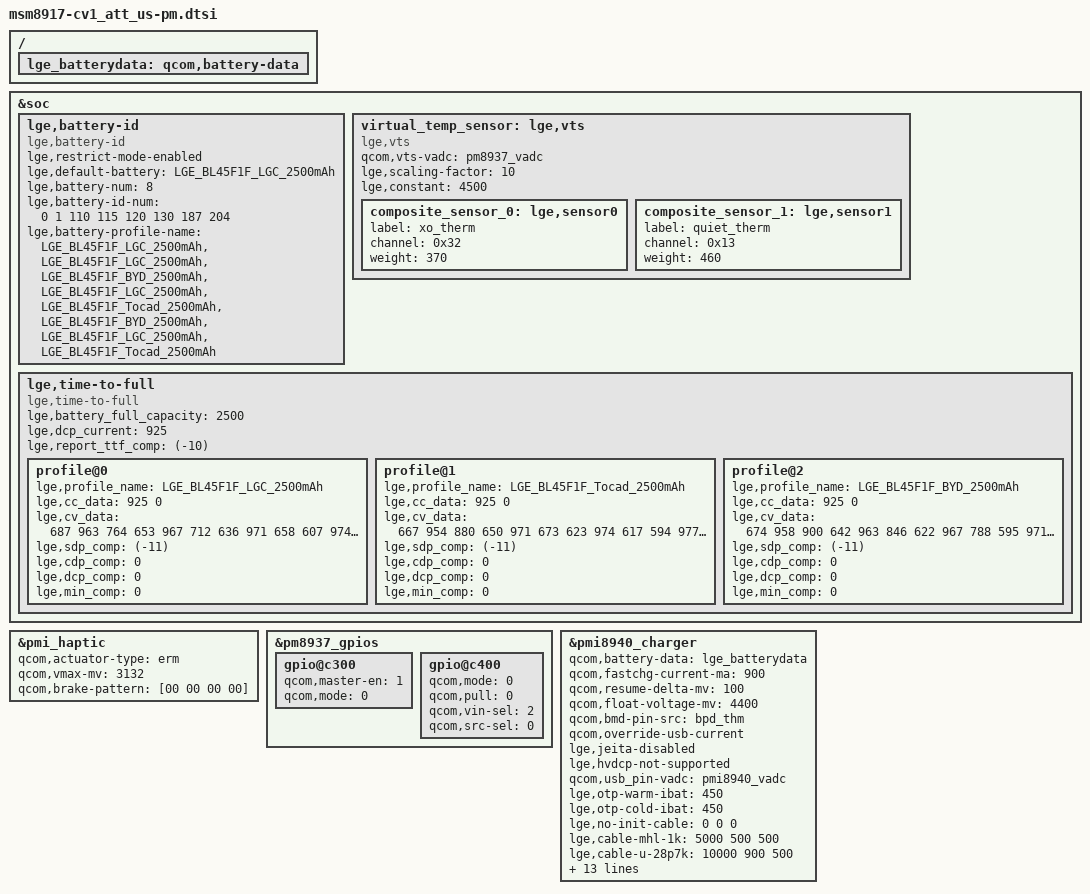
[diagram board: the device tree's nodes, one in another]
/*
 * Copyright (c) 2016, The Linux Foundation. All rights reserved.
 *
 * This program is free software; you can redistribute it and/or modify
 * it under the terms of the GNU General Public License version 2 and
 * only version 2 as published by the Free Software Foundation.
 *
 * This program is distributed in the hope that it will be useful,
 * but WITHOUT ANY WARRANTY; without even the implied warranty of
 * MERCHANTABILITY or FITNESS FOR A PARTICULAR PURPOSE.  See the
 * GNU General Public License for more details.
 */

/{
    lge_batterydata: qcom,battery-data {
         #include "../battery_profile/LGE_BL45F1F_LGC_2500mAh.dtsi"
         #include "../battery_profile/LGE_BL45F1F_Tocad_2500mAh.dtsi"
         #include "../battery_profile/LGE_BL45F1F_BYD_2500mAh.dtsi"
    };
};

&soc {
	lge,battery-id{
		compatible = "lge,battery-id";
		lge,restrict-mode-enabled;
		/*default battery profile*/
		lge,default-battery = "LGE_BL45F1F_LGC_2500mAh";
		/*Total number of combined of battery cell and battery id */
		lge,battery-num = <8>;
		/* battery id and battery profile match numbers */
		lge,battery-id-num = <0 1 110 115 120 130 187 204>;
		/* battery profile */
		lge,battery-profile-name = "LGE_BL45F1F_LGC_2500mAh",
						"LGE_BL45F1F_LGC_2500mAh",
						"LGE_BL45F1F_BYD_2500mAh",
						"LGE_BL45F1F_LGC_2500mAh",
						"LGE_BL45F1F_Tocad_2500mAh",
						"LGE_BL45F1F_BYD_2500mAh",
						"LGE_BL45F1F_LGC_2500mAh",
						"LGE_BL45F1F_Tocad_2500mAh";
	};

	/* vts = (0.37*xo_therm) + (0.46*quiet_therm) + 4.5 */
	virtual_temp_sensor: lge,vts {
		compatible = "lge,vts";
		qcom,vts-vadc = <&pm8937_vadc>;
		lge,scaling-factor= <10>;
		lge,constant = <4500>;
		composite_sensor_0: lge,sensor0 {
			label = "xo_therm";
			channel = <0x32>;
			weight = <370>;
		};
		composite_sensor_1: lge,sensor1 {
			label = "quiet_therm";
			channel = <0x13>;
			weight = <460>;
		};
	};

	/* time to full */
	lge,time-to-full {
		compatible = "lge,time-to-full";
		lge,battery_full_capacity = <2500>;
		lge,dcp_current = <925>;
		lge,report_ttf_comp = <(-10)>;
		profile@0 {
			lge,profile_name = "LGE_BL45F1F_LGC_2500mAh";
				    /* current  soc */
			lge,cc_data = < 925 0 >;
				    /* current  soc    time */
			lge,cv_data = < 687 963 764
							653 967 712
							636 971 658
							607 974 601
							587 977 542
							558 980 482
							540 983 420
							511 986 355
							490 989 289
							469 993 220
							452 996 150
							428 999 76
							411 1000 0 >;
			lge,sdp_comp = <(-11)>;
			lge,cdp_comp = <0>;
			lge,dcp_comp = <0>;
			lge,min_comp = <0>;
		};
		profile@1 {
			lge,profile_name = "LGE_BL45F1F_Tocad_2500mAh";
				    /* current  soc */
			lge,cc_data = < 925 0 >;
				    /* current  soc    time */
			lge,cv_data = < 667 954 880
							650 971 673
							623 974 617
							594 977 556
							568 980 495
							546 983 429
							520 986 363
							502 989 295
							472 993 225
							453 996 152
							425 999 77
							412 1000 0 >;
			lge,sdp_comp = <(-11)>;
			lge,cdp_comp = <0>;
			lge,dcp_comp = <0>;
			lge,min_comp = <0>;
		};
		profile@2 {
			lge,profile_name = "LGE_BL45F1F_BYD_2500mAh";
				    /* current  soc */
			lge,cc_data = < 925 0 >;
				    /* current  soc    time */
			lge,cv_data = < 674 958 900
							642 963 846
							622 967 788
							595 971 728
							574 974 667
							545 977 603
							531 980 537
							500 983 468
							482 986 398
							455 989 325
							438 993 247
							414 996 168
							399 999 86
							374 1000 0 >;
			lge,sdp_comp = <(-11)>;
			lge,cdp_comp = <0>;
			lge,dcp_comp = <0>;
			lge,min_comp = <0>;
		};
	};
};

&pmi_haptic{
	status = "okay";
	qcom,actuator-type = "erm";
	qcom,vmax-mv = <3132>;
	qcom,brake-pattern = [00 00 00 00];
};

&pm8937_gpios {
	gpio@c300 {
		qcom,master-en = <1>;
		qcom,mode = <0>;
		status = "okay";
	};

	gpio@c400 {
		qcom,mode = <0>;
		qcom,pull = <0>;
		qcom,vin-sel = <2>;
		qcom,src-sel = <0>;
		status = "okay";
	};
};

&pmi8940_charger {
	qcom,battery-data = <&lge_batterydata>;
	qcom,fastchg-current-ma = <900>;
	qcom,resume-delta-mv = <100>;
	qcom,float-voltage-mv = <4400>;
	qcom,bmd-pin-src = "bpd_thm";
	qcom,override-usb-current;
	lge,jeita-disabled;
	lge,hvdcp-not-supported;

	qcom,usb_pin-vadc = <&pmi8940_vadc>;

	lge,otp-warm-ibat = <450>;
	lge,otp-cold-ibat = <450>;

	/* ref resistance 200K */
	lge,no-init-cable = <0 0 0>;
	lge,cable-mhl-1k = <5000 500 500>;
	lge,cable-u-28p7k = <10000 900 500>;
	lge,cable-28p7k = <250000 900 500>;
	lge,cable-56k = <600000 1500 1500>;
	lge,cable-100k = <620000 900 500>;
	lge,cable-130k = <780000 1500 1500>;
	lge,cable-180k = <870000 900 500>;
	lge,cable-200k = <910000 900 500>;
	lge,cable-220k = <960000 900 500>;
	lge,cable-270k = <1050000 900 500>;
	lge,cable-330k = <1150000 900 500>;
	lge,cable-620k = <1380000 900 500>;
	lge,cable-910k = <1630000 1500 1500>;
	lge,cable-none = <1900000 900  500>;

	lge,usb-max-current-ma = <900>;
};
